# SAPH_A_367.0 register map
Vendor: Texas Instruments
Peripheral module from a debugger description file (folder msp430).
Registers are 16-bit, read-write, no defined reset value unless marked. A register's access mark holds for its fields unless they carry their own. Offsets are as the file gives them; lines under a group give offsets from that group; [hi:lo] are bit positions; {n}, {i} and the like mark numbered series; 'fields as' and 'values as' point back to an identical list; <NAME> marks a mode.

## SAPH_A
0x00 SAPH_AIIDX ro — Interrupt Index
  [3:1] IIDX — This register provides the highest priority enabled interrupt index.
    0=NONE (no interrupts pending); 1=DATAERR (This interrupt indicates that either WINHI interrupt or WINLO interrupt has occurred in SDHS.); 2=TMFTO (This interrupt is valid when ASQ is activcve (auto mode). The interrupt indicates that the time counter in ASQ has reached to TIMEMARK_F (timeout).); 3=SEQDN (This interrupt is valid when ASQ is activcve (auto mode). The interrupt occurs when ASQ completes all of the measurements programmed in ASCTL0.PNGCNT. For example, when ASCTL0.PNGCNT = 3, total four measurements are performed. The interrupt indicates that all of the four measurements have been completed.); 4=PNGDN (This interrupt is valid when ASQ is active (auto mode). The interrupt occurs when ASQ completes one measurement sequence. For example, when ASCTL0.PNGCNT = 3, total four measurements are performed. The interrupt indicates that one measurement has been completed.)
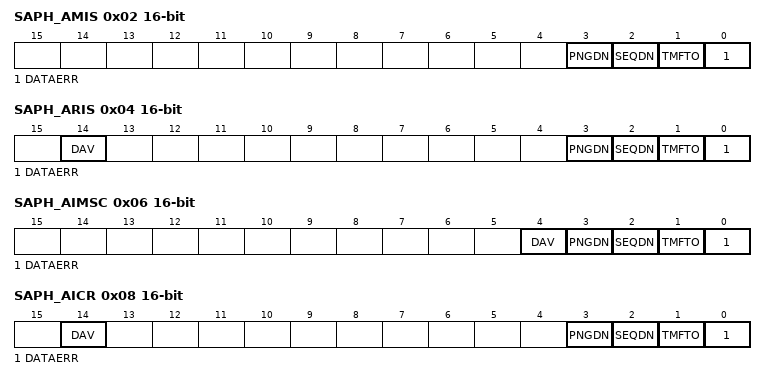
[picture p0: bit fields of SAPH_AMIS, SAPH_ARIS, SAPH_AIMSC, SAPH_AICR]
0x02 SAPH_AMIS ro — Masked Interrupt Satus
  [3] PNGDN — This interrupt is valid when ASQ is active (auto mode). The interrupt occurs when ASQ completes one measurement sequence. For example, when ASCTL0.PNGCNT = 3, total four measurements are performed. The interrupt indicates that one measurement has been completed.
  [2] SEQDN — This interrupt is valid when ASQ is activcve (auto mode). The interrupt occurs when ASQ completes all of the measurements programmed in ASCTL0.PNGCNT. For example, when ASCTL0.PNGCNT = 3, total four measurements are performed. The interrupt indicates that all of the four measurements have been completed.
  [1] TMFTO — This bit indicates a TIMEMARK F (timeout) event has happened.
  [0] DATAERR — This interrupt indicates that either WINHI interrupt or WINLO interrupt has occurred in SDHS.
0x04 SAPH_ARIS ro — Raw Interrupt Status
  [14] DAV — This bit indicates a DMA access violation
  [3] PNGDN — This interrupt is valid when ASQ is active (auto mode). The interrupt occurs when ASQ completes one measurement sequence. For example, when ASCTL0.PNGCNT = 3, total four measurements are performed. The interrupt indicates that one measurement has been completed.
  [2] SEQDN — This interrupt is valid when ASQ is activcve (auto mode). The interrupt occurs when ASQ completes all of the measurements programmed in ASCTL0.PNGCNT. For example, when ASCTL0.PNGCNT = 3, total four measurements are performed. The interrupt indicates that all of the four measurements have been completed.
  [1] TMFTO — This bit indicates a TIMEMARK F (timeout) event has happened.
  [0] DATAERR — This interrupt indicates that either WINHI interrupt or WINLO interrupt has occurred in SDHS.
0x06 SAPH_AIMSC access per field — Interrupt Mask
  [4] DAV ro — This bit indicates a DMA access violation
  [3] PNGDN rw — This bit enables the PNGDN interrupt
  [2] SEQDN rw — This bit enables the SEQDN interrupt
  [1] TMFTO rw — This bit enables the TIMEMARK F (timeout) interrupt.
  [0] DATAERR rw — This bit enables the DATAERR interrupt.
0x08 SAPH_AICR — Interrupt Clear
  [14] DAV — Writing one this bit to clear any previous DMA access violations
  [3] PNGDN — Writing one this bit to clear the pending PNGDN interrupt.
  [2] SEQDN — Writing one this bit to clear the pending SEQDN interrupt.
  [1] TMFTO — Writing one this bit to clear the pending TIMEMARK F (timeout) interrupt
  [0] DATAERR — Writing one this bit to clear the pending DATAERR interrupt.
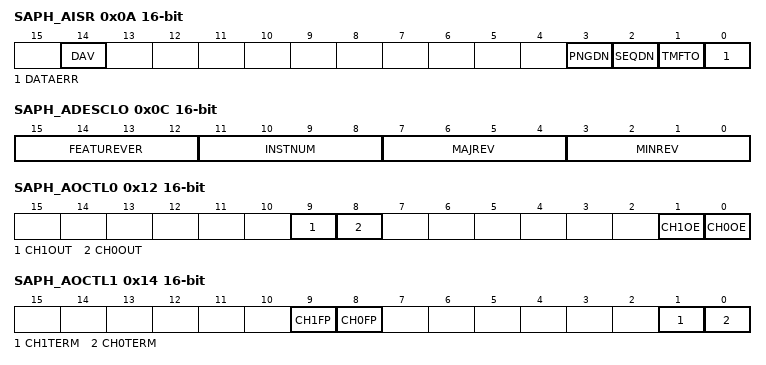
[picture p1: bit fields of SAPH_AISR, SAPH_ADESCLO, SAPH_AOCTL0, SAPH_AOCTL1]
0x0A SAPH_AISR — Interrupt Set
  [14] DAV — Writing one this bit to set RIS.DAV by software.
  [3] PNGDN — Writing one this bit to generate a PNGDN interrupt by software.
  [2] SEQDN — Writing one this bit to generate a SEQDN interrupt by software.
  [1] TMFTO — Writing one this bit to generate a TIMEMARK F (timeout) interrupt by software.
  [0] DATAERR — Writing one this bit generates a DATAERR interrupt by software.
0x0C SAPH_ADESCLO ro — Module-Descriptor Low Word
  [15:12] FEATUREVER — Feature Version
  [11:8] INSTNUM — Instance Number
  [7:4] MAJREV — Major Revision
  [3:0] MINREV — Minor Revision
0x0E SAPH_ADESCHI access not given — Module-Descriptor High Word
0x10 SAPH_AKEY access not given — Key
0x12 SAPH_AOCTL0 — Physical Interface Output Control #0
  [9] CH1OUT — CH1_OUT Value. When OSEL.PCH1SEL =0 and OCTL0.CH1OE=1, this bit represents the logical value on the CH1 terminal. 0 = low 1 = high
    0=Ch1 is set to low signal; 1=Ch1 is set to high signal
  [8] CH0OUT — CH0_OUT Value. When OSEL.PCH0SEL =0 and OCTL0.CH0OE=1, this bit represents the logical value on the CH0 terminal. 0 = low 1 = high
    0=Ch0 is set to low signal; 1=Ch0 is set to high signal
  [1] CH1OE — CH1_OUT Enable. When OSEL.PCH1SEL =0, this bit enables the output CH1 when set to 1. When OSEL.PCH1SEL != 0, this bit is invalid.
    0=Ch1 Output is HiZ; 1=CH1 Output is driving
  [0] CH0OE — CH0_OUT Enable. When OSEL.PCH0SEL =0, this bit enables the output CH0 when set to 1. When OSEL.PCH0SEL != 0, this bit is invalid.
    0=Ch0 Output is HiZ; 1=CH0 Output is driving
0x14 SAPH_AOCTL1 — Physical Interface Output Control #1
  [9] CH1FP — DRV1 (output driver on the CH1_OUT) full strength enable. 0 = The DRV1 output impedance is deterimed by CH1PUT and CH1PDT registers. 1 = The DRV1 has lowest output impedance.
    0=Ch1 Output is set to normal strength; 1=Ch1 Output is set to maximum strength
  [8] CH0FP — DRV0 (output driver on the CH0_OUT) full strength enable. 0 = The DRV0 output impedance is deterimed by CH0PUT and CH0PDT registers. 1 = The DRV0 has lowest output impedance.
    0=Ch0 Output is set to normal strength; 1=Ch0 Output is set to maximum strength
  [1] CH1TERM — CH1 termination switch (SWG1) enable. When OSEL.PCH1SEL =0, this bit controls the SWG1 switch. 0 = SWG1 is off. 1 = SWG1 is on. The CH1_OUT is disabled and connected to PVSS via SWG1 switch. No need to change OCTL0.CH1OE status.
    0=CH1 Output is defined by CH1OUT and CH1OE; 1=CH1 Output is set low with termination strength
  [0] CH0TERM — CH0 termination switch (SWG0) enable. When OSEL.PCH0SEL =0, this bit controls the SWG0 switch. 0 = SWG0 is off. 1 = SWG0 is on. The CH0_OUT is disabled and connected to PVSS via SWG0 switch. No need to change OCTL0.CH0OE status.
    0=CH0 Output is defined by CH0OUT and CH0OE; 1=CH0 Output is set low with termination strength
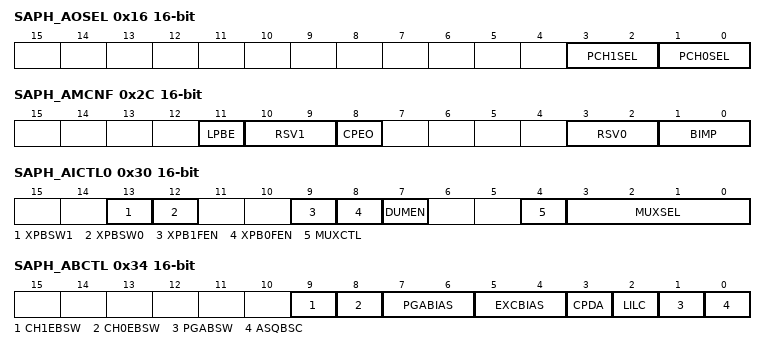
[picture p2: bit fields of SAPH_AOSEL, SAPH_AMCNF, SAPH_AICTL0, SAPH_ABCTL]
0x16 SAPH_AOSEL — Physical Interface Output Function Select
  [3:2] PCH1SEL — Output functional select for CH0_OUT.
    0=GPIO (CH1_OUT is used as a GPO pin. It is controlled by OCTL0.CH1OUT and OCTL0.CH1OE.); 1=PPGSE (CH1_OUT is driven by the PPG.); 2=CH1_OUT is driven by the PPG as differential output along with CH0_OUT. (CH0_OUT and CH1_OUT are alwasy opposite polarity); 3=CH1_OUT is used as a GPO pin. It is controlled by OCTL0.CH1OUT and OCTL0.CH1OE.
  [1:0] PCH0SEL — Output functional select for CH0_OUT.
    0=GPIO (CH0_OUT is used as a GPO pin. It is controlled by OCTL0.CH0OUT and OCTL0.CH0OE.); 1=PPGSE (CH0_OUT is driven by the PPG.); 2=CH0_OUT is driven by the PPG as differential output along with CH1_OUT. (CH0_OUT and CH1_OUT are alwasy opposite polarity); 3=CH0_OUT is used as a GPO pin. It is controlled by OCTL0.CH0OUT and OCTL0.CH0OE.
0x20 SAPH_ACH0PUT — Channel 0 Pull UpTrim Register
  [3:0] CH0PUT — DRV0 pull up trim register. Write access is allowed only when TACR.UNLOCK=1. For secure the trim value, it is recommended to keep TACR.UNLOCK=0 during normal operation.
0x22 SAPH_ACH0PDT — Channel 0 Pull DownTrim Register
  [3:0] CH0PDT — DRV0 pull down trim register. Write access is allowed only when TACR.UNLOCK=1. For secure the trim value, it is recommended to keep TACR.UNLOCK=0 during normal operation.
0x24 SAPH_ACH0TT — Channel 0 Termination Trim
  [3:0] CH0TT — SWG0 trim register. Write access is allowed only when TACR.UNLOCK=1. For secure the trim value, it is recommended to keep TACR.UNLOCK=0 during normal operation.
0x26 SAPH_ACH1PUT — Channel 1 Pull UpTrim
  [3:0] CH1PUT — DRV1 pull up trim register. Write access is allowed only when TACR.UNLOCK=1. For secure the trim value, it is recommended to keep TACR.UNLOCK=0 during normal operation.
0x28 SAPH_ACH1PDT — Channel 1 Pull DownTrim
  [3:0] CH1PDT — DRV1 pull down trim register. Write access is allowed only when TACR.UNLOCK=1. For secure the trim value, it is recommended to keep TACR.UNLOCK=0 during normal operation.
0x2A SAPH_ACH1TT — Channel 1 Termination Trim
  [3:0] CH1TT — SWG1 trim register. Write access is allowed only when TACR.UNLOCK=1. For secure the trim value, it is recommended to keep TACR.UNLOCK=0 during normal operation.
0x2C SAPH_AMCNF — Mode Configuration Register
  [11] LPBE — LPBE, low power bias mode enable. This bit enables the low power bias operation mode. The selection of the operation mode shall only be changed while the PSQ is in OFF state (changes during other states of the PSQ causes corrupt measurement results and irregular triggers of sub modules ba ASQ)
    0=For manual bias mode and regular ASQ bias mode. In this configuration the user controls by the ASQBSW has full control over the TxBias and RxBias switches.; 1=Low power bias mode. In this mode the ASQ uses the CHxEBSW and PGABSW as auxiliary values to achieve faster channel setting on reactive input loads. The ASQ has full controls over the bias switch multiplexer.
  [10:9] RSV1 — Reserved for future use
  [8] CPEO — This bit enables the charge pump of the input multiplexer.
    0=Charge pump is turned on by SDHS and ASQ related requests only; 1=Charge pump is turned on regardless of SDHS and ASQ related charge pump requests
  [3:2] RSV0 — Reserved for future use
  [1:0] BIMP — These bits define the impedance of the buffers for RxBias and TxBias. While for resistive loads the lowest impedance shows the fastest settling; is this not the case for reactive loads.
    0=200 Ohms buffer impedance for RxBias and TxBias; 1=600 Ohms buffer impedance for RxBias and TxBias; 2=1200 Ohms buffer impedance for RxBias and TxBias (default); 3=2800 Ohms buffer impedance for RxBias and TxBias
0x2E SAPH_ATACTL — Trim Access Control
  [0] UNLOCK — When UNLOCK = 1, the trim registers are allowed to be updated (CH0PUT, CH0PDT, CH0TT, CH1PUT, CH1PDT, and CH1TT).
0x30 SAPH_AICTL0 — Physical Interface Input Control #0
  [13] XPBSW1 — External PGA Bias Switch 1 control
    0=External bias switch is open (no bias driven); 1=External bias switch is closed (bias is driven)
  [12] XPBSW0 — External PGA Bias Switch 0 control
    values as XPBSW1
  [9] XPB1FEN — XPB1 Pin Function Enable
    0=XPB1 pin function disabled; 1=XPB1 pin function enabled
  [8] XPB0FEN — XPB0 Pin Function Enable
    0=XPB0 pin function disabled; 1=XPB0 pin function enabled
  [7] DUMEN — PGA dummy load enable on the deselected multiplexer inputs.
    0=PGA dummy input load is Hi-Z; 1=PGA dummy input load matches the PGA input impedance
  [4] MUXCTL — Input Multiplexer Control source
    0=The input multiplexer is controlled by ICTL0.MUXSEL (register mode); 1=The input multiplexer is controlled by ASQ (auto mode)
  [3:0] MUXSEL — Input Multiplexer Channel Select
    0=CH0IN (Channel 0 is selected for input); 1=CH1IN (Channel 1 is selected for input); {v}=reserved for future channels (v=2..7); {v}=no channel is selected (v=8..15)
0x34 SAPH_ABCTL — Bias Control
  [9] CH1EBSW — Channel 1 Tx bias Switch Control. Note that the Tx bias voltage is determined by BCTL.EXCBIAS.
    0=Tx bias switch to CH1 is open; 1=Tx bias switch to CH1 is closed (enabled)
  [8] CH0EBSW — Channel 0 Tx bias Switch Control. Note that the Tx bias voltage is determined by BCTL.EXCBIAS.
    0=Tx bias switch to CH0 is open; 1=Tx bias switch to CH0 is closed (enabled)
  [7:6] PGABIAS — PGA bias (Rx bias) Voltage Select
    0=0.75V nominal; 1=0.8V nominal; 2=0.9V nominal; 3=0.95V nominal
  [5:4] EXCBIAS — Excitation bias (Rx bias) Voltage Select
    0=0.2V nominal; 1=0.3V nominal; 2=0.4V nominal; 3=0.6V nominal
  [3] CPDA — Enable the power supply (Charge Pump) for the the input multiplexer during data acquisition.
    0=Turn off the charge pump during data acquisition; 1=Keep turning on the charge pump during data acquisition
  [2] LILC — Line input leakage compensation (LILC) enable.
    0=LICL is disabled; 1=LICL is enabled
  [1] PGABSW — Rx bias (PGA bias) switch control. Note that the channel to apply the Rx bias is determined by ICTL0.MUXSEL.
    0=Rx bias switch is open; 1=Rx bias switch is closed (enabled)
  [0] ASQBSC — Tx bias and Rx bias switches control source select
    0=Bias switches are controlled by BCTL.CH0EBSW, BCTL.CH1EBSW, BCTL.PGABSW bits (register mode); 1=Bias switches are controlled by ASQ (auto mode)
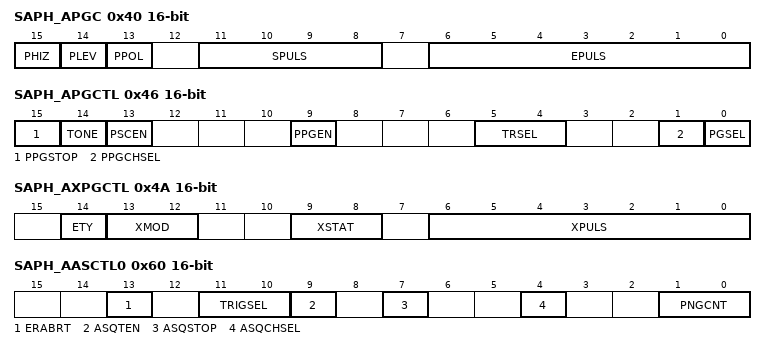
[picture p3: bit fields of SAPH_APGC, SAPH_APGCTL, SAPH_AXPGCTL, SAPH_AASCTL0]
0x40 SAPH_APGC — PPG Count
  [15] PHIZ — Hi-Z enable to PPG output during inactive.
    0=PPG output during inactive is determined by PGC.PLEV bit; 1=PPG output is in Hi-Z during inactive regardless of PGC.PLEV bit
  [14] PLEV — PPG ouptut level during inactive. This bit affects the status of PPG output before and after excitations. Note that this bit is only valid when PGC.PHIZ =0.
    0=PPG output is low during inactive; 1=PPG output is high during inactive
  [13] PPOL — Pulse Polarity. This bit defines the polarity of the first excitation pulse.
    0=The excitation begins with logical high phase. The stop begines with logical low phase.; 1=The excitation begins with logical low phase. The stop begines with logical high phase.
  [11:8] SPULS — Stop Pulse Count; This bit field defines the number of stop pulses. Minimum value is zero. Stop pulses have the inverted polarity of excitation pulses.
  [6:0] EPULS — Excitation Pulse Count. This bit field defines the number of excitation pulses. Minimum value is zero.
0x42 SAPH_APGLPER — Pulse Generator Low Period
  [7:0] LPER — Low phase period of PPG excitation pulses. This value defines the length of the low phase of the pulses. The minimum count is two regardless of the value set in this register.
0x44 SAPH_APGHPER — Pulse Generator High Period
  [7:0] HPER — High phase period of PPG excitation pulses. This value defines the length of the high phase of the pulses. The minimum count is two regardless of the value set in this register.
0x46 SAPH_APGCTL — PPG Control
  [15] PPGSTOP — Writing one to this bit stopps the PPG to generate pulses. This bit is cleared automatically.
  [14] TONE — Tone generation enable. The frequency of the test tone is determined by LPER and HPER. The test tone persists while PGCTL.TONE = 1 & PGCTL.STOP=0. Either writing 0 to PGCTL.TONE or writing 1 to PGCTL.STOP stops tone generation.
    0=DISABLE (Test tone generation is disabled. Note: This bit is automatically cleared when writing '1' to PGCTL.STOP, and it stops test tone generation immediately.); 1=ENABLE (Test tone generation is enabled.)
  [13] PSCEN — PPG pre scaler enable.
    0=DISABLE (Prescaler is disabled. PPG clock = PLL output clock.); 1=ENABLE (Prescaler by four is enabled. PPG clock = 1/4 of the PLL output clock.)
  [9] PPGEN — PPGEN PPG trigger enable. This bit can be used to indicates that the configuration of the pulse generator is complete. The PPG can only be started when this bit is set to 1 regardless of its trigger source. It is recommended to keep this bit zero while updating PPG registers.
    0=PPG trigger is disabled; 1=PPG trigger is enabled
  [5:4] TRSEL — PPG Trigger source select.
    0=Writing 1 to PPGTRIG.PPGTRIG to trigger the PPG (start pulse generation); 1=PPG trigger is controlled by the ASQ; 2=Ext. Signal (See device specific datasheet); 3=Ext. Signal (See device specific datasheet)
  [1] PPGCHSEL — PPG output channel select when PGCTL.PGSEL = 0.
    0=CH0 is selected; 1=CH1 is selected
  [0] PGSEL — PPG output channel select source.
    0=PPG output channel is selected by PGCTL.PPGCHSEL bit (register mode); 1=PPG output channel is selected by ASQ (auto mode)
0x48 SAPH_APPGTRIG — PPG Software Trigger
  [0] PPGTRIG — Writing '1' to this bit triggers the PPG to generate pulses when PGCTL.TRSEL =0. Note: This bit is write only. Reading always returns with zero.
0x4A SAPH_AXPGCTL access per field — Extended Pulse Control Register
  [14] ETY rw — Event type. Selects the type of the event generated in XMOD=3
    0=Timer count event; 1=DMA trigger event
  [13:12] XMOD rw — Extended Mode Select
    0=Single tone generation (Pause-E-S-Pause); 2=Dual Tone Generation (Pause-X-E-S-Pause); 3=Dual Tone Loop (X-E-X-E triggers events)
  [9:8] XSTAT ro — Phase Status of PPG
    0=PPG in Pause Phase; 1=PPG in Stop Phase; 2=PPG in Regular Excitation phase; 3=PPG in Extra Excitation Phase
  [6:0] XPULS rw — XPULS Extra Pulse Count; This bit field defines the count of extra excitation pulses excited. If set to zero no extra excitation pulses are generated. Directly after the start the regular excitation phase is entered. Any other number will generate up the number of excitation pulses set by this field .
0x4C SAPH_AXPGLPER — Extra Pulse Low Period Register
  [7:0] XLPER — XLPER low phase period of the extra pulses. This value defines the length of the low phase of the extra pulses in units of high speed clocks. The minimum count is two regardless of the value set in this register.
0x4E SAPH_AXPGHPER — Extra Pulse High Period Register
  [7:0] XHPER — XHPER high phase period of the extra pulses. This value defines the length of the high phase of the pulses in units of high speed clocks. The minimum count is two regardless of the value set in this register.
0x60 SAPH_AASCTL0 — A-SEQ control register 0
  [13] ERABRT — Stop ASQ when the DATAERR interrupt occurrs when the mesurements controlled by ASQ (auto mode). Note that it is not possible to resume the measurement from where it was stopped. When ASQ is triggered again, the measurement seqeunce starts from the beginning.
    0=Continue the measurements until completion regardless of the DATAERR interrupt; 1=Stop the ASQ upon the DATAERR interrupt
  [11:10] TRIGSEL — ASQ trigger select.
    0=SWTRIG (Writing '1' to ASQTRIG.ASQTRIG); 1=PSQ (The PSQ is selected to start the ASQ.); 2=TIMER (Ext. Signal (See device specific datasheet)); 3=Ext. Signal (See device specific datasheet)
  [9] ASQTEN — ASQ Trigger Enable. This bit can be used to indicate that the configuration of the ASQ is complete. The ASQ can only be triggered when this bit is set to '1' regardless of its trigger source. It is recommended to keep this bit zero while updating ASQ registerds.
    0=ASQEN_0 (ASQ trigger is disabled.); 1=ASQEN_1 (ASQ trigger is enabled.)
  [7] ASQSTOP — Stop the ASQ. Writing '1' to this bit stops the measurement sequence controlled by the ASQ. This bit is self cleared.
  [4] ASQCHSEL — This bit selects the channel to start with when ASQ contols the measuremnet sequences.
    0=CH0 is selected to start with. If ASCTL0.PNGCNT = 3 and ASCTL1.CHTOG =1, then the channel selection would be CH0 - CH1 - CH0 - CH1. If ASCTL0.PNGCNT = 3 and ASCTL1.CHTOG =0, then the channel selection would be CH0 - CH0 - CH0 - CH0.; 1=CH1 is selected to start with. If ASCTL0.PNGCNT = 3 and ASCTL1.CHTOG =0, then the channel selection would be CH1 - CH1 - CH1 - CH1. If ASCTL0.PNGCNT = 3 and ASCTL1.CHTOG =1, then the channel selection would be CH1 - CH0 - CH1 - CH0.
  [1:0] PNGCNT — The total number of measurements to be performed. 0 = 1 measurement will be performed (Min) 1 = 2 measurements will be performed 2 = 3 measurements will be performed 3 = 4 measurements will be performed (Max) Note: This bit field is static, does not reflect the currently reamining measurement numbers.
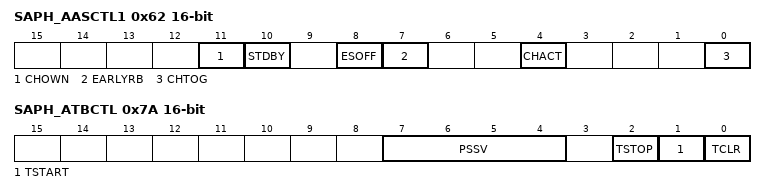
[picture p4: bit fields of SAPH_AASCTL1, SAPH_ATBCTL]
0x62 SAPH_AASCTL1 access per field — A-SEQ control register 1
  [11] CHOWN rw — In general, if CH0 is selected for Tx, CH1 is selected for Rx. However, when this bit is set to '1', the Tx channel and Rx channel are identical. This bit can be used for debugging purpose.
    0=Tx channel and Rx channel are not the same (This is the typical configuration); 1=Tx channel and Rx channel are identical
  [10] STDBY rw — ASQ can send a request sigal to the PSQ (Power Sequencer) of the USS module when the OFF request is received (See ASCTL1.ESOFF and the UUPS module).
    0=PWROFF (The ASQ sends a power down request to the PSQ (Power Sequencer) when the OFF request is received.); 1=STDBY (The ASQ sends a standby request to the PSQ (Power Sequencer) when the OFF request is received.)
  [8] ESOFF rw — Enable the OFF request when ASQ completes all of the measurement sequences.
    0=OFF request is disabled. The ASQ does not send a request about USS power mode to the PSQ.; 1=OFF request is generated after sequence
  [7] EARLYRB rw — Early Receive Bias Control. The Rx bias is applied at the TIMEMARK C, but when this bit is set to '1', the Rx bias is applied at the TIMEMARK A.
    0=Rx bias is applied to the Rx channel by the TIMEMARK C; 1=Rx bias is applied to the Rx channel by the TIMEMARK A
  [4] CHACT ro — Read Only bit. This bit indicates the currently selected Tx channel.
  [0] CHTOG rw — Channel toggle enable at each PNGDN interrupt.
    0=Channel toggle is disabled; 1=Channel toggle is enabled at each PNGDN interrupt
0x64 SAPH_AASQTRIG 8-bit — ASQ Software Trigger
  [0] ASQTRIG — Writing '1' to this bit trigger the ASQ when ASCTL0.TRIGSEL = 0. Note: This bit is write only. Reading always returns with zero.
0x66 SAPH_AAPOL — ASQ ping output polarity
  [3:0] PCPOL — Bit 0 defines the PPG pulse polarity for the first measurement. Bit 1 defines the PPG pulse polarity for the second measurement. Bit 2 defines the PPG pulse polarity for the third measurement. Bit 3 defines the PPG pulse polarity for the fourth measurement. 0 = PPG output pulses starts with logical high polarity. 1 = PPG output pulses starts with logical low polarity.
0x68 SAPH_AAPLEV — ASQ ping pause level
  [3:0] PCPLEV — Bit 0 defines the PPG output level at pause for the first measurement when PCPHIZ bit 0 = 0. Bit 1 defines the PPG output level at pause for the second measurement when PCPHIZ bit 1 = 0. Bit 2 defines the PPG output level at pause for the third measurement when PCPHIZ bit 2 = 0. Bit 3 defines the PPG output level at pause for the fourth measurement when PCPHIZ bit 3 = 0. 0 = Logical Low. 1 = Logical High.
0x6A SAPH_AAPHIZ — ASQ ping pause impedance
  [3:0] PCPHIZ — Bit 0 defines the PPG output status at pause for the first measurement. Bit 1 defines the PPG output status at pause for the second measurement. Bit 2 defines the PPG output status at pause for the third measurement. Bit 3 defines the PPG output status at pause for the fourth measurement. 0 = PPG ouput level is determined by APLEV.PCPLEV bits 1 = Hi-z. regardless of APLEV.PCPLEV bits
0x6E SAPH_AATM_A access not given — A-SEQ start to 1st ping
0x70 SAPH_AATM_B access not given — ASQ start to ADC arm
0x72 SAPH_AATM_C access not given — Count for the TIMEMARK C Event
0x74 SAPH_AATM_D access not given — ASQ start to ADC trig
0x76 SAPH_AATM_E access not given — ASQ start to restart
0x78 SAPH_AATM_F access not given — ASQ start to timeout
0x7A SAPH_ATBCTL — Time Base Control
  [7:4] PSSV — ASQ pre-scaler shift. The value written to the PSSV bits shifts the start point of the ASQ's pre-scaler. Note that the value only affects the first cycle of the pre-scaler. 0 = No shift 1 = The pre-scaler starts 1 clock later 2 = The pre-scaler starts 2 clocks later ... 15 = The pre-scaler starts 15 clocks later
  [2] TSTOP — The ASQ time counter stop. Writing '1' to this bit stops the counter. This bit is self cleared. TSTOP, TSTART, and TCLR bits are offerred for only debugging purpose. It is not recommend to use this bit while ASQ is active. Note: This bit is write only. Reading always returns with zero.
  [1] TSTART — The ASQ time counter start. Writing '1' to this bit starts the counter. This bit is self cleared. TSTOP, TSTART, and TCLR bits are offerred for only debugging purpose. It is not recommend to use this bit while ASQ is active. Note: This bit is write only. Reading always returns with zero.
  [0] TCLR — The ASQ time counter clear. Writing '1' to this bit clears the the counter value. The counter must be stopped prior to be cleared. This bit is self cleared. TSTOP, TSTART, and TCLR bits are offerred for only debugging purpose. It is not recommend to use this bit while ASQ is active. Note: This bit is write only. Reading always returns with zero.
0x7C SAPH_AATIMLO access not given — Acquisition Timer Low Part
0x7E SAPH_AATIMHI ro — Acquisition Timer High Part
  [3:0] ATIMHI — ASQ Timer Counter high part. The reading this register returns the counter value [19:16].
